# MSS_IOMUX_IOMUX_53100000h register map
Vendor: Texas Instruments
Peripheral module from a debugger description file (folder AM261x).
Registers are 32-bit, access per field, reset values left out (the file's numbers can be read two ways) unless marked. A register's access mark holds for its fields unless they carry their own. Offsets are as the file gives them; lines under a group give offsets from that group; [hi:lo] are bit positions; {n}, {i} and the like mark numbered series; 'fields as' and 'values as' point back to an identical list; <NAME> marks a mode.

## IOMUX
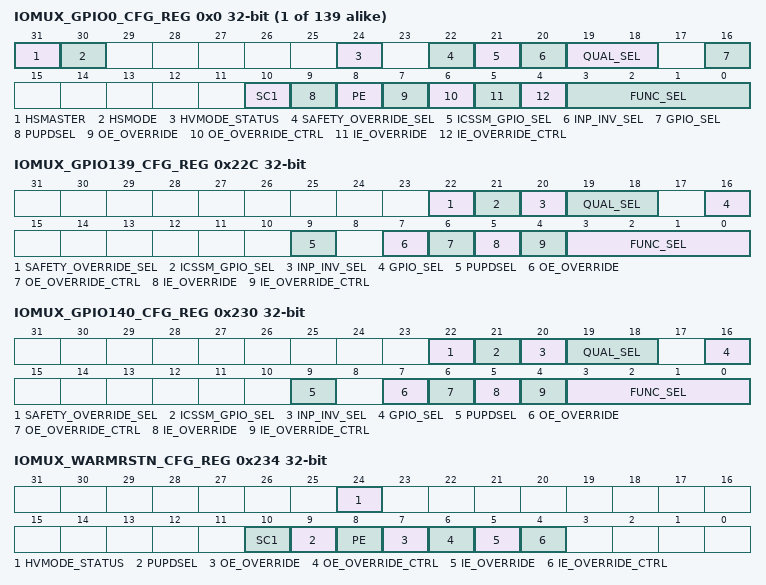
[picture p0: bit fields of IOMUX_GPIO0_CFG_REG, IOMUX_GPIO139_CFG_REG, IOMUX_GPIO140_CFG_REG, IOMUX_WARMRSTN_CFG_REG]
{0x0+4i} IOMUX_GPIO{i}_CFG_REG (i=0..138)
  [31] HSMASTER rw — MMR bits for HSMASTER pin incase of true I2C pads
  [30] HSMODE rw — MMR bits for HSMODE pin incase of true I2C pads
  [24] HVMODE_STATUS ro — IO Power group indication0:1.8V Power Domain1:3.3V Power Domain
  [22] SAFETY_OVERRIDE_SEL rw — mux Select Value to choose between Actual IO pad input and Safety override mux output1 Safety override mux output is selected0 Actual IO pad input is selected
  [21] ICSSM_GPIO_SEL rw — mux Select Value to choose between ICSSM_GPIO and normal GPIO 1 ICSSM_GPIO is selected0 Normal GPIO is selected
  [20] INP_INV_SEL rw — Select Value for chosing inverted version of PAD input for chip:0 : Non Inverted1 : Inverted
  [19:18] QUAL_SEL rw — Select Value for chosing input qualifer type for PAD.00 : Sync, 01 : 3 Sample qual 10 : 6 Samples qual 11 : Async
  [16] GPIO_SEL rw — R5F CPU ownership select for GPIO.0 : GPO0, 1 :GPO1
  [10] SC1 rw — IO Slew Rate Control :0 : higher slew rate.1:Lower slew rate.
  [9] PUPDSEL rw — Pullup/PullDown Selection 0 -- Pull Down 1 - Pull Up
  [8] PE rw — PE = Pull Enable [Active Low]0 = Pull Enabled1 = Pull Disabled
  [7] OE_OVERRIDE rw — Active Low Output Override
  [6] OE_OVERRIDE_CTRL rw — Active Low Output Override Control : Write 1 to select Active low Output Override value to control IOs OE_N/GZ instead of the control from hardware
  [5] IE_OVERRIDE rw — Active Low Input Override
  [4] IE_OVERRIDE_CTRL rw — Active Low Input Override Control : Write 1 to select Active low Input Override value to control IOs IE_N/RXACTIVE_N instead of the control from hardware
  [3:0] FUNC_SEL rw — Function select
0x22C IOMUX_GPIO139_CFG_REG rw
  [22] SAFETY_OVERRIDE_SEL — mux Select Value to choose between Actual IO pad input and Safety override mux output1 Safety override mux output is selected0 Actual IO pad input is selected
  [21] ICSSM_GPIO_SEL — mux Select Value to choose between ICSSM_GPIO and normal GPIO 1 ICSSM_GPIO is selected0 Normal GPIO is selected
  [20] INP_INV_SEL — Select Value for chosing inverted version of PAD input for chip:0 : Non Inverted1 : Inverted
  [19:18] QUAL_SEL — Select Value for chosing input qualifer type for PAD.00 : Sync, 01 : 3 Sample qual 10 : 6 Samples qual 11 : Async
  [16] GPIO_SEL — R5F CPU ownership select for GPIO.0 : GPO0, 1 :GPO1
  [9] PUPDSEL — Pullup/PullDown Selection 0 -- Pull Down 1 - Pull Up
  [7] OE_OVERRIDE — Active Low Output Override
  [6] OE_OVERRIDE_CTRL — Active Low Output Override Control : Write 1 to select Active low Output Override value to control IOs OE_N/GZ instead of the control from hardware
  [5] IE_OVERRIDE — Active Low Input Override
  [4] IE_OVERRIDE_CTRL — Active Low Input Override Control : Write 1 to select Active low Input Override value to control IOs IE_N/RXACTIVE_N instead of the control from hardware
  [3:0] FUNC_SEL — Function select
0x230 IOMUX_GPIO140_CFG_REG rw
  fields as IOMUX_GPIO139_CFG_REG
0x234 IOMUX_WARMRSTN_CFG_REG
  [24] HVMODE_STATUS ro — IO Power group indication0:1.8V Power Domain1:3.3V Power Domain
  [10] SC1 rw — IO Slew Rate Control :0 : higher slew rate.1:Lower slew rate.
  [9] PUPDSEL rw — Pullup/PullDown Selection 0 -- Pull Down 1 - Pull Up
  [8] PE rw — PE = Pull Enable [Active Low]0 = Pull Enabled1 = Pull Disabled
  [7] OE_OVERRIDE rw — Active Low Output Override
  [6] OE_OVERRIDE_CTRL rw — Active Low Output Override Control : Write 1 to select Active low Output Override value to control IOs OE_N/GZ instead of the control from hardware
  [5] IE_OVERRIDE rw — Active Low Input Override
  [4] IE_OVERRIDE_CTRL rw — Active Low Input Override Control : Write 1 to select Active low Input Override value to control IOs IE_N/RXACTIVE_N instead of the control from hardware
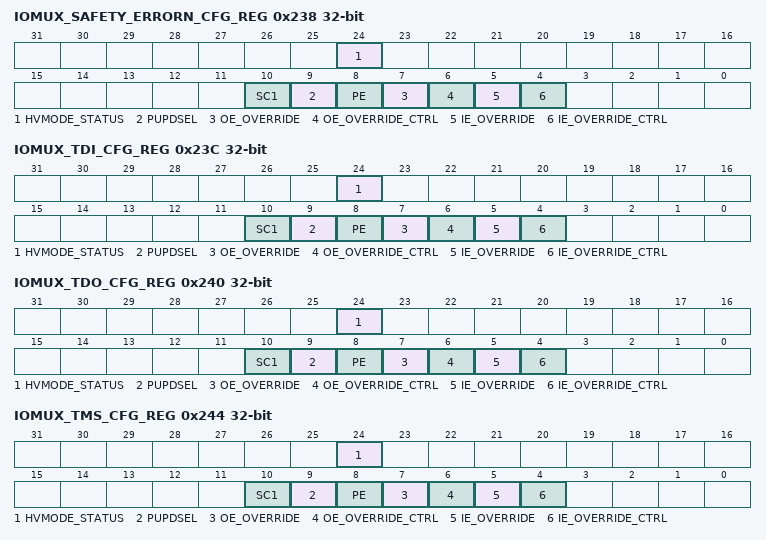
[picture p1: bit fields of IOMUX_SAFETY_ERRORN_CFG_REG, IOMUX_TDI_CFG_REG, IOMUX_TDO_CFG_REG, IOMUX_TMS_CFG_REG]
0x238 IOMUX_SAFETY_ERRORN_CFG_REG
  fields as IOMUX_WARMRSTN_CFG_REG
0x23C IOMUX_TDI_CFG_REG
  fields as IOMUX_WARMRSTN_CFG_REG
0x240 IOMUX_TDO_CFG_REG
  fields as IOMUX_WARMRSTN_CFG_REG
0x244 IOMUX_TMS_CFG_REG
  fields as IOMUX_WARMRSTN_CFG_REG
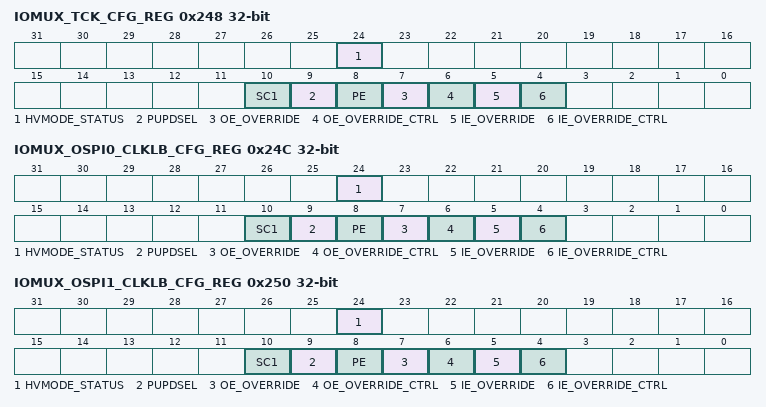
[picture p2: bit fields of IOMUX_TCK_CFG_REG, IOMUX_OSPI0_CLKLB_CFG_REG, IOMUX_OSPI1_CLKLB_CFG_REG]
0x248 IOMUX_TCK_CFG_REG
  fields as IOMUX_WARMRSTN_CFG_REG
0x24C IOMUX_OSPI0_CLKLB_CFG_REG
  fields as IOMUX_WARMRSTN_CFG_REG
0x250 IOMUX_OSPI1_CLKLB_CFG_REG
  fields as IOMUX_WARMRSTN_CFG_REG
{0x254+4i} IOMUX_QUAL_GRP_{i}_CFG_REG rw (i=0..17)
  [7:0] QUAL_PERIOD_PER_SAMPLE — MMR bits for programming the qualifier clock count per sample
0x29C IOMUX_USER_MODE_EN rw
  [31:0] USER_MODE_EN — Write 0XADADADAD to enable user mode write access to IO CFG space
0x2A0 IOMUX_PADGLBL_CFG_REG rw
  [31:0] PADGLBL_CFG_REG — 20 : global_ie_n_ctl - Write 3'b111 to pass global_ie_n_val to IE_N/RXACTIVE_N pin of all the IOs.3 : global_ie_n_val - Active low108 : global_oe_n_ctl - Write 3'b111 to pass global_oe_n_val to OE_N/GZ pin of all the IOs.11 : global_oe_n_val - Active low1816 : global_pi_ctl - Write 3'b111 to pass global_pi_val and global_pu_val to all the IOs19 : global_pi_val20 : global_pu_val
0x2A4 IOMUX_IO_CFG_KICK0 rw
  [31:0] IO_CFG_KICK0 — Kicker 0 Register. The value 83E7 0B13h must be written to KICK0 as part of the process to unlock the CPU.write access to the above PIN MUX registers [including IOCFGKICK1]
0x2A8 IOMUX_IO_CFG_KICK1 rw
  [31:0] IO_CFG_KICK1 — Kicker 1 Register. The value 95A4 F1E0h must be written to the KICK1 as part of the process to unlock the CPU write access to above PINMUX registers [excluding IOCFGKICK0]. IOCFGKICK0 has to be written with 83E70B13h to enable access to IOCFGKICK1.
